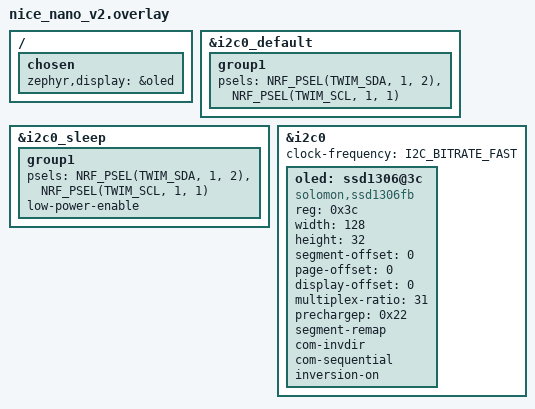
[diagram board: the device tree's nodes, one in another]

/**
 * Generated by Shield Wizard for ZMK
 * Applies to shield "u_3x6_3" with board "nice_nano_v2" only
 */

//
// ======== i2c0 ========
//

// pin control for i2c0
// - SDA on P1.02
// - SCL on P1.01
&i2c0_default {
    group1 {
        psels = <NRF_PSEL(TWIM_SDA, 1, 2)>,
                <NRF_PSEL(TWIM_SCL, 1, 1)>;
    };
};
&i2c0_sleep {
    group1 {
        psels = <NRF_PSEL(TWIM_SDA, 1, 2)>,
                <NRF_PSEL(TWIM_SCL, 1, 1)>;
        low-power-enable;
    };
};
&i2c0 {
  status = "okay";
  clock-frequency = <I2C_BITRATE_FAST>;
};

// devices on i2c0

&i2c0 {
    oled: ssd1306@3c {
        compatible = "solomon,ssd1306fb";
        reg = <0x3c>;
        width = <128>;
        height = <32>;

        segment-offset = <0>;
        page-offset = <0>;
        display-offset = <0>;
        multiplex-ratio = <31>;
        prechargep = <0x22>;
        segment-remap;
        com-invdir;
        com-sequential;
        inversion-on;
    };
};
/ {
    chosen {
        zephyr,display = &oled;
    };
};
